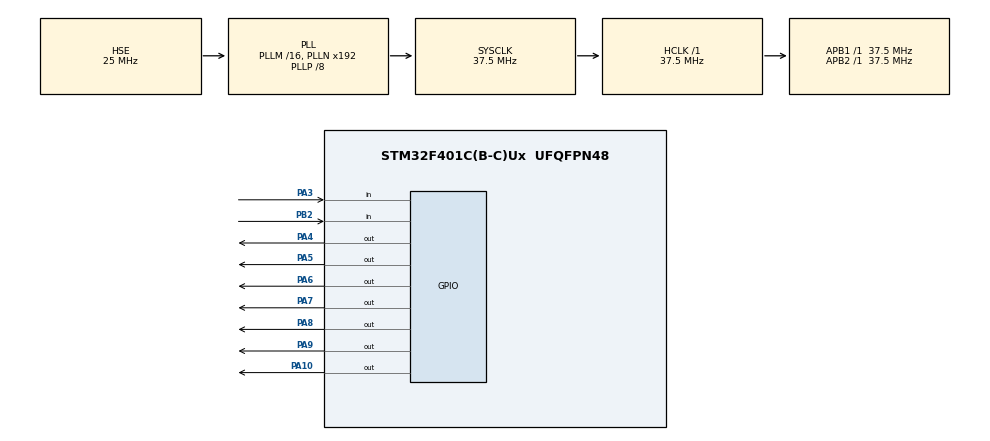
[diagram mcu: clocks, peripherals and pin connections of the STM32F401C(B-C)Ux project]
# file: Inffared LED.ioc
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Mcu.Family=STM32F4
Mcu.Name=STM32F401C(B-C)Ux
Mcu.Package=UFQFPN48
NVIC.PriorityGroup=NVIC_PRIORITYGROUP_4
PA10.Signal=GPIO_Output
PA3.Signal=GPIO_Input
PA4.Signal=GPIO_Output
PA5.Signal=GPIO_Output
PA6.Signal=GPIO_Output
PA7.Signal=GPIO_Output
PA8.Signal=GPIO_Output
PA9.Signal=GPIO_Output
PB2.Signal=GPIO_Input
PC14-OSC32_IN.Mode=LSE-External-Oscillator
PC14-OSC32_IN.Signal=RCC_OSC32_IN
PC15-OSC32_OUT.Mode=LSE-External-Oscillator
PC15-OSC32_OUT.Signal=RCC_OSC32_OUT
PH0\ -\ OSC_IN.Mode=HSE-External-Oscillator
PH0\ -\ OSC_IN.Signal=RCC_OSC_IN
PH1\ -\ OSC_OUT.Mode=HSE-External-Oscillator
PH1\ -\ OSC_OUT.Signal=RCC_OSC_OUT
ProjectManager.HeapSize=0x200
ProjectManager.StackSize=0x400
ProjectManager.TargetToolchain=STM32CubeIDE
RCC.48MHZClocksFreq_Value=75000000
RCC.AHBFreq_Value=37500000
RCC.APB1Freq_Value=37500000
RCC.APB1TimFreq_Value=37500000
RCC.APB2Freq_Value=37500000
RCC.APB2TimFreq_Value=37500000
RCC.CortexFreq_Value=37500000
RCC.HCLKFreq_Value=37500000
RCC.HSE_VALUE=25000000
RCC.HSI_VALUE=16000000
RCC.PLLP=RCC_PLLP_DIV8
RCC.PLLSourceVirtual=RCC_PLLSOURCE_HSE
RCC.SYSCLKFreq_VALUE=37500000
RCC.SYSCLKSource=RCC_SYSCLKSOURCE_PLLCLK
RCC.VCOOutputFreq_Value=300000000
board=custom

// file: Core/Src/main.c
/* USER CODE BEGIN Header */
/**
  ******************************************************************************
  * @file           : main.c
  * @brief          : Main program body
  ******************************************************************************
  * @attention
  *
  * Copyright (c) 2024 STMicroelectronics.
  * All rights reserved.
  *
  * This software is licensed under terms that can be found in the LICENSE file
  * in the root directory of this software component.
  * If no LICENSE file comes with this software, it is provided AS-IS.
  *
  ******************************************************************************
  */
/* USER CODE END Header */
#include "main.h"

void SystemClock_Config(void);
static void MX_GPIO_Init(void);

int main(void)
{

  /* MCU Configuration--------------------------------------------------------*/

  /* Reset of all peripherals, Initializes the Flash interface and the Systick. */
  HAL_Init();

  /* USER CODE BEGIN Init */
  uint8_t LED[] = {0x3F,0x06,0x5B,0x4F,0x66,0x6D,0x7D,0x07,0x7F,0x67,0x77,0x7C,0x39,0x5E,0x79,0x71};
  /* USER CODE END Init */

  /* Configure the system clock */
  SystemClock_Config();

  /* Initialize all configured peripherals */
  MX_GPIO_Init();
  /* USER CODE BEGIN 2 */
  int state_past = 0;
  int count = 0;
  int past = HAL_GetTick();
  int value = 0;
  /* USER CODE END 2 */

  /* Infinite loop */
  /* USER CODE BEGIN WHILE */
  while (1)
  {
	  if (HAL_GetTick() - past > 300){
		  value = HAL_GPIO_ReadPin(GPIOB, GPIO_PIN_0);
		  past = HAL_GetTick();
		  if (value == 0){
			  GPIOA->ODR = ~(uint32_t)LED[0]<<4;
		  }
		  if (value!=state_past&&value==1){
			  count ++;
			  GPIOA->ODR = ~(uint32_t)LED[count]<<4;
		  }
		  state_past = value;
	  }

    /* USER CODE END WHILE */

  }
}

void SystemClock_Config(void)
{
  RCC_OscInitTypeDef RCC_OscInitStruct = {0};
  RCC_ClkInitTypeDef RCC_ClkInitStruct = {0};

  /** Configure the main internal regulator output voltage
  */
  __HAL_RCC_PWR_CLK_ENABLE();
  __HAL_PWR_VOLTAGESCALING_CONFIG(PWR_REGULATOR_VOLTAGE_SCALE2);

  /** Initializes the RCC Oscillators according to the specified parameters
  * in the RCC_OscInitTypeDef structure.
  */
  RCC_OscInitStruct.OscillatorType = RCC_OSCILLATORTYPE_HSE;
  RCC_OscInitStruct.HSEState = RCC_HSE_ON;
  RCC_OscInitStruct.PLL.PLLState = RCC_PLL_ON;
  RCC_OscInitStruct.PLL.PLLSource = RCC_PLLSOURCE_HSE;
  RCC_OscInitStruct.PLL.PLLM = 16;
  RCC_OscInitStruct.PLL.PLLN = 192;
  RCC_OscInitStruct.PLL.PLLP = RCC_PLLP_DIV8;
  RCC_OscInitStruct.PLL.PLLQ = 4;
  if (HAL_RCC_OscConfig(&RCC_OscInitStruct) != HAL_OK)
  {
    Error_Handler();
  }

  /** Initializes the CPU, AHB and APB buses clocks
  */
  RCC_ClkInitStruct.ClockType = RCC_CLOCKTYPE_HCLK|RCC_CLOCKTYPE_SYSCLK
                              |RCC_CLOCKTYPE_PCLK1|RCC_CLOCKTYPE_PCLK2;
  RCC_ClkInitStruct.SYSCLKSource = RCC_SYSCLKSOURCE_PLLCLK;
  RCC_ClkInitStruct.AHBCLKDivider = RCC_SYSCLK_DIV1;
  RCC_ClkInitStruct.APB1CLKDivider = RCC_HCLK_DIV1;
  RCC_ClkInitStruct.APB2CLKDivider = RCC_HCLK_DIV1;

  if (HAL_RCC_ClockConfig(&RCC_ClkInitStruct, FLASH_LATENCY_1) != HAL_OK)
  {
    Error_Handler();
  }
}

static void MX_GPIO_Init(void)
{
  GPIO_InitTypeDef GPIO_InitStruct = {0};

  /* GPIO Ports Clock Enable */
  __HAL_RCC_GPIOC_CLK_ENABLE();
  __HAL_RCC_GPIOH_CLK_ENABLE();
  __HAL_RCC_GPIOA_CLK_ENABLE();
  __HAL_RCC_GPIOB_CLK_ENABLE();

  /*Configure GPIO pin Output Level */
  HAL_GPIO_WritePin(GPIOA, GPIO_PIN_4|GPIO_PIN_5|GPIO_PIN_6|GPIO_PIN_7
                          |GPIO_PIN_8|GPIO_PIN_9|GPIO_PIN_10, GPIO_PIN_RESET);

  /*Configure GPIO pin : PA3 */
  GPIO_InitStruct.Pin = GPIO_PIN_3;
  GPIO_InitStruct.Mode = GPIO_MODE_INPUT;
  GPIO_InitStruct.Pull = GPIO_NOPULL;
  HAL_GPIO_Init(GPIOA, &GPIO_InitStruct);

  /*Configure GPIO pins : PA4 PA5 PA6 PA7
                           PA8 PA9 PA10 */
  GPIO_InitStruct.Pin = GPIO_PIN_4|GPIO_PIN_5|GPIO_PIN_6|GPIO_PIN_7
                          |GPIO_PIN_8|GPIO_PIN_9|GPIO_PIN_10;
  GPIO_InitStruct.Mode = GPIO_MODE_OUTPUT_PP;
  GPIO_InitStruct.Pull = GPIO_NOPULL;
  GPIO_InitStruct.Speed = GPIO_SPEED_FREQ_LOW;
  HAL_GPIO_Init(GPIOA, &GPIO_InitStruct);

  /*Configure GPIO pin : PB2 */
  GPIO_InitStruct.Pin = GPIO_PIN_2;
  GPIO_InitStruct.Mode = GPIO_MODE_INPUT;
  GPIO_InitStruct.Pull = GPIO_NOPULL;
  HAL_GPIO_Init(GPIOB, &GPIO_InitStruct);

}

void Error_Handler(void)
{
  __disable_irq();
  while (1)
  {
  }
}
